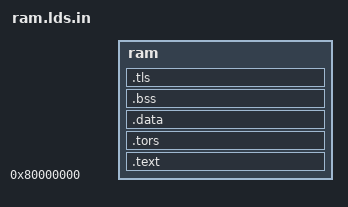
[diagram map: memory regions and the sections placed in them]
OUTPUT_ARCH( "riscv" )
ENTRY(_entry)

MEMORY
{
  ram : ORIGIN = 0x80000000, LENGTH = __RISCV_QEMU_MEMORY_SIZE__
}

SECTIONS
{
	.text :
	{
		. = ALIGN(16);  /* %jp{128bit命令を想定して16バイトアラインに設定} */
		 ___text = . ;
		*/crt0.o(.text)
		*(.text .text.*)
		*(.rodata*)
		*(.strings)
		*(.glue*)
		 ___text_end = . ;
	} > ram

	.tors :
	{
		. = ALIGN(16);  /* %jp{128bit命令を想定して16バイトアラインに設定} */
		___ctors = . ;
		*(.ctors)
		___ctors_end = . ;
		___dtors = . ;
		*(.dtors)
		___dtors_end = . ;
	} > ram
	.data : AT (ADDR(.tors) + SIZEOF(.tors))
	{
		/* %jp{128bitロード/ストアを想定して16バイトアラインに設定} */
		. = ALIGN(16);
		___data = . ;
		*(.data)
		_gp = ALIGN(16) + 0x800;
		*(.sdata)
		___data_end = . ;
	} > ram
	.bss :
	{
		/* %jp{128bitロード/ストアを想定して16バイトアラインに設定} */
		. = ALIGN(16);
		___bss = . ;
		*(.sbss)
		*(.bss)
		*(COMMON)
		*(.scommon)
		___bss_end = . ;
	} > ram

	/* %jp{128bitロード/ストアを想定して16バイトアラインに設定} */
	. = ALIGN(16);

	.tls :
	{
		_tp = . ; /* %jp{Thread Local Storage領域開始アドレス} */
		___tls_data = . ;
		*(.tdata)
		___tls_data_end = . ;
		___tls_bss = . ;
		*(.tbss)
		___tls_bss_end = . ;
	} > ram

}
